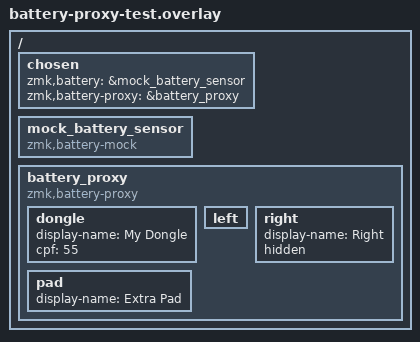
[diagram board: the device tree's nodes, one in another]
/*
 * Copyright (c) 2024 The ZMK Contributors
 *
 * SPDX-License-Identifier: MIT
 */

/ {
    chosen {
        zmk,battery = &mock_battery_sensor;
        zmk,battery-proxy = &battery_proxy;
    };

    mock_battery_sensor: mock_battery_sensor {
        compatible = "zmk,battery-mock";
    };

    battery_proxy: battery_proxy {
        compatible = "zmk,battery-proxy";

        dongle {
            display-name = "My Dongle";
            cpf = <55>;
        };
        left {
            // display-name = "Left";
            // cpf = <50>;
        };
        right{
            display-name = "Right";
            hidden;
        };
        pad{
            display-name = "Extra Pad";
        };
    };
};
